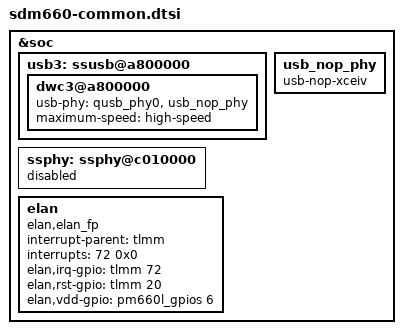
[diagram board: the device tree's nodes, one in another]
/* Copyright (c) 2016-2017, The Linux Foundation. All rights reserved.
 *
 * This program is free software; you can redistribute it and/or modify
 * it under the terms of the GNU General Public License version 2 and
 * only version 2 as published by the Free Software Foundation.
 *
 * This program is distributed in the hope that it will be useful,
 * but WITHOUT ANY WARRANTY; without even the implied warranty of
 * MERCHANTABILITY or FITNESS FOR A PARTICULAR PURPOSE.  See the
 * GNU General Public License for more details.
 */

&soc {
	usb3: ssusb@a800000 {
		dwc3@a800000 {
			usb-phy = <&qusb_phy0>, <&usb_nop_phy>;
			maximum-speed = "high-speed";
		};
	};

	usb_nop_phy:usb_nop_phy {
		compatible = "usb-nop-xceiv";
	};

	ssphy: ssphy@c010000 {
		status = "disabled";
	};

	elan { 
		compatible = "elan,elan_fp";
		interrupt-parent = <&tlmm>;
		interrupts = <72 0x0>;
		elan,irq-gpio = <&tlmm 72 0x00>;
		elan,rst-gpio = <&tlmm 20 0x00>;
		elan,vdd-gpio = <&pm660l_gpios 6 0>;
	};
};
